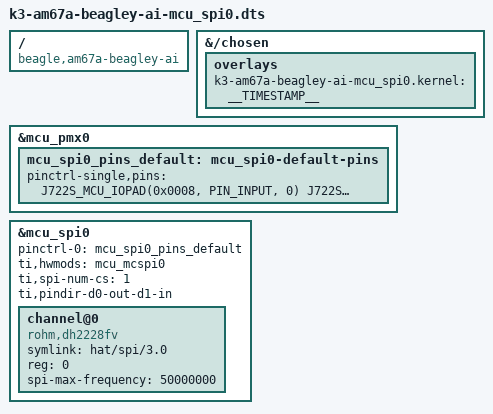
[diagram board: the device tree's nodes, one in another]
// SPDX-License-Identifier: GPL-2.0
/*
 * DT Overlay for spidev3.0 & spidev3.1 (mcspi) on BeagleY-AI board.
 *
 * Copyright (C) 2023 Texas Instruments Incorporated - https://www.ti.com/
 *
 */

/dts-v1/;
/plugin/;

#include <dt-bindings/gpio/gpio.h>
#include <dt-bindings/interrupt-controller/irq.h>
#include "ti/k3-pinctrl.h"

/*
 * Helper to show loaded overlays under: /proc/device-tree/chosen/overlays/
 */
&{/chosen} {
    overlays {
        k3-am67a-beagley-ai-mcu_spi0.kernel = __TIMESTAMP__;
    };
};

/ {
    compatible = "beagle,am67a-beagley-ai", "ti,j722s";
    
    fragment@0 {
        target = <&mcu_pmx0>;
        __overlay__ {
            mcu_spi0_pins_default: mcu_spi0-default-pins {
                pinctrl-single,pins = <
                    // Note: MCU_SPI0_CS1 on (A10) connects to MCU_OBSCLK0 and unavailable.
                    // Note: MCU_SPI0_CS2 on (B3)  shared with spidev0 ce1 and WKUP_UART0_RXD.
                    J722S_MCU_IOPAD(0x0008, PIN_INPUT,  0) /* (A9)  MCU_SPI0_CLK */
                    J722S_MCU_IOPAD(0x0000, PIN_OUTPUT, 0) /* (C12) MCU_SPI0_CS0 */
                    J722S_MCU_IOPAD(0x000c, PIN_INPUT,  0) /* (B12) MCU_SPI0_D0 */
                    J722S_MCU_IOPAD(0x0010, PIN_INPUT,  0) /* (C11) MCU_SPI0_D1 */
                >;
            };
        };
    };
    

    fragment@1 {
        target = <&mcu_spi0>;
        __overlay__ {
            status = "okay";
            #address-cells = <1>;
            #size-cells = <0>;
            pinctrl-names = "default";
            pinctrl-0 = <&mcu_spi0_pins_default>;

            ti,hwmods = "mcu_mcspi0";
            ti,spi-num-cs = <1>;
            
            //ti,pindir-d0-in-d1-out;
            ti,pindir-d0-out-d1-in;

            channel@0 {
                symlink = "hat/spi/3.0";
                compatible = "rohm,dh2228fv";
                reg = <0>;	/* CE0 */
                spi-max-frequency = <50000000>;
                status = "okay";
            };
        };
    };
};
